AUTOSAR XML (schema 4.0)
package /Powertrain
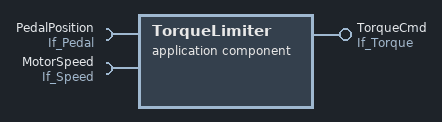
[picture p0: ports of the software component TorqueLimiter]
  application sw component type TorqueLimiter
    require port PedalPosition: required-interface=If_Pedal
    require port MotorSpeed: required-interface=If_Speed
    provide port TorqueCmd: provided-interface=If_Torque
